AUTOSAR XML (schema 4-2-2)
package /Components
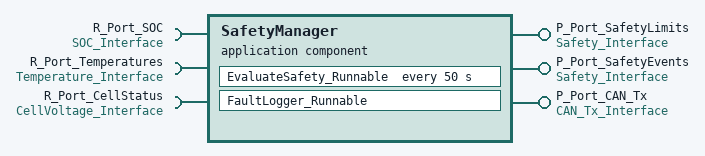
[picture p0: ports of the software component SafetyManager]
  application sw component type SafetyManager
    provide port P_Port_SafetyLimits: provided-interface=Safety_Interface
    provide port P_Port_SafetyEvents: provided-interface=Safety_Interface
    provide port P_Port_CAN_Tx: provided-interface=CAN_Tx_Interface
    require port R_Port_SOC: required-interface=SOC_Interface
    require port R_Port_Temperatures: required-interface=Temperature_Interface
    require port R_Port_CellStatus: required-interface=CellVoltage_Interface
    behavior SafetyManager_Behavior
      data received event CriticalData_In: start-on-event=EvaluateSafety_Runnable
      timing event Safety_Check_50ms: start-on-event=EvaluateSafety_Runnable, period=50
      transformer hard error event Hardware_Failure: start-on-event=FaultLogger_Runnable
      runnable EvaluateSafety_Runnable: minimum-start-interval=50, symbol=SafetyManager_EvaluateSafety
        data-receive-point-by-arguments:
          5 x access:
            Read_SOC: accessed-variable=R_Port_SOC.SOC
            Read_SOH: accessed-variable=R_Port_SOC.SOH
            Read_Confidence: accessed-variable=R_Port_SOC.confidence
            Read_Temperatures: accessed-variable=R_Port_Temperatures.temperatures
            Read_CellVoltageSummary: accessed-variable=R_Port_CellStatus.cellVoltageSummary
        data-send-points:
          access Write_SafetyLimits: accessed-variable=P_Port_SafetyLimits.safetyLimits
          access Write_SafetyEvent: accessed-variable=P_Port_SafetyEvents.safetyEvent
        data-write-access:
          access Log_To_CAN: accessed-variable=P_Port_CAN_Tx.CAN_Frame
      runnable FaultLogger_Runnable: minimum-start-interval=1000, symbol=SafetyManager_FaultLogger
        data-receive-point-by-arguments:
          access Receive_Event_For_Logging: accessed-variable=P_Port_SafetyEvents.safetyEvent
        data-send-points:
          access Send_Logged_CAN: accessed-variable=P_Port_CAN_Tx.CAN_Frame
        data-write-access:
          access Write_Event_Record: accessed-variable=P_Port_SafetyEvents.safetyEvent
